AUTOSAR XML (schema 4-3-0)
package /Impl_SWC_FDC_ARPkg
  swc implementation Impl_SWC_FDC_type: programming-language=C, sw-version=1.0.0, vendor-id=0, behavior=SWC_FDC_type_IB
    code-descriptors:
      code SRC: artifact-descriptors=autosar-engineering-object={short-label=EngObject, category=SWSRC}
    resource consumption ResourceConsumption
      memory section MEM_SWC_FDC_CAL: size=0, sw-addrmethod=CAL, symbol=CAL
      memory section MEM_SWC_FDC_CODE: size=0, sw-addrmethod=CODE, symbol=CODE
package /SWC_FDC_ARPkg
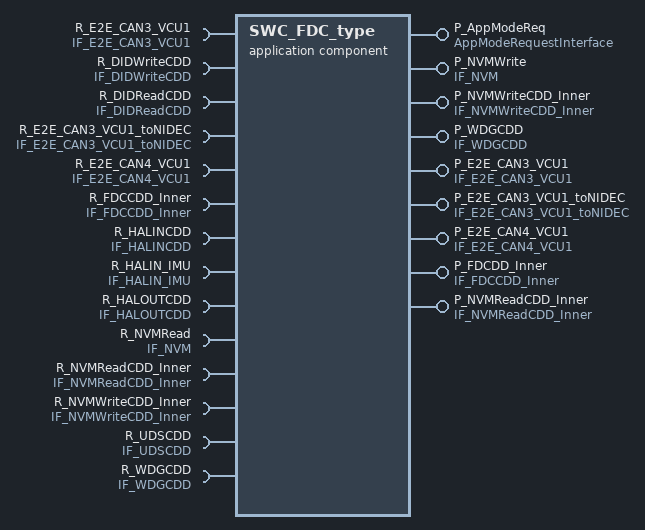
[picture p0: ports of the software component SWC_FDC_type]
  application sw component type SWC_FDC_type
    9 x provide port:
      P_AppModeReq: provided-interface=AppModeRequestInterface
      P_NVMWrite: nv-provide-com-spec{ram-block-init-value=ValueSpecification_:256 x 0, rom-block-init-value=ValueSpecification_:256 x 0, variable=NV_FVTDataArray}, provided-interface=IF_NVM
      P_NVMWriteCDD_Inner: provided-interface=IF_NVMWriteCDD_Inner
      P_WDGCDD: provided-interface=IF_WDGCDD
      P_E2E_CAN3_VCU1: provided-interface=IF_E2E_CAN3_VCU1
      P_E2E_CAN3_VCU1_toNIDEC: provided-interface=IF_E2E_CAN3_VCU1_toNIDEC
      P_E2E_CAN4_VCU1: provided-interface=IF_E2E_CAN4_VCU1
      P_FDCDD_Inner: provided-interface=IF_FDCCDD_Inner
      P_NVMReadCDD_Inner: provided-interface=IF_NVMReadCDD_Inner
    14 x require port:
      R_E2E_CAN3_VCU1: required-interface=IF_E2E_CAN3_VCU1
      R_DIDWriteCDD: required-interface=IF_DIDWriteCDD
      R_DIDReadCDD: required-interface=IF_DIDReadCDD
      R_E2E_CAN3_VCU1_toNIDEC: required-interface=IF_E2E_CAN3_VCU1_toNIDEC
      R_E2E_CAN4_VCU1: required-interface=IF_E2E_CAN4_VCU1
      R_FDCCDD_Inner: required-interface=IF_FDCCDD_Inner
      R_HALINCDD: required-interface=IF_HALINCDD
      R_HALIN_IMU: required-interface=IF_HALIN_IMU
      R_HALOUTCDD: required-interface=IF_HALOUTCDD
      R_NVMRead: nv-require-com-spec{init-value=256 x 0, variable=NV_FVTDataArray}, required-interface=IF_NVM
      R_NVMReadCDD_Inner: required-interface=IF_NVMReadCDD_Inner
      R_NVMWriteCDD_Inner: required-interface=IF_NVMWriteCDD_Inner
      R_UDSCDD: required-interface=IF_UDSCDD
      R_WDGCDD: required-interface=IF_WDGCDD
    behavior SWC_FDC_type_IB: data-type-mapping=AppModeTypeMap, handle-termination-and-restart=NO-SUPPORT
      5 x timing event:
        TE_10ms: start-on-event=run_SWC_FDC_Tx_10ms, period=0.01
        TE_5ms: start-on-event=run_SWC_FDC_RxTx_5ms, period=0.005
        TE_CDD_10ms: start-on-event=run_SWC_FDC_CDD_10ms, period=0.01
        TE_PAS_1ms: start-on-event=run_SWC_FDC_PAS_1ms, period=0.001
        TE_UDS_10ms: start-on-event=run_SWC_FDC_UDS_10ms, period=0.01
      9 x operation invoked event:
        oie_P_E2E_CAN3_VCU1_CSOP_Write_CAN3_VCU1: start-on-event=run_SWC_FDC_E2E_Write_CAN3VCU1, operation=P_E2E_CAN3_VCU1.CSOP_Write_CAN3_VCU1
        oie_P_E2E_CAN3_VCU1_CSOP_Write_CAN3_VCU1_toNIDEC: start-on-event=run_SWC_FDC_E2E_Write_CAN3VCU1_toNIDEC, operation=P_E2E_CAN3_VCU1_toNIDEC.CSOP_Write_CAN3_VCU1_toNIDEC
        oie_P_E2E_CAN4_VCU1_CSOP_Write_CAN4_VCU1: start-on-event=run_SWC_FDC_E2E_Write_CAN4VCU1, operation=P_E2E_CAN4_VCU1.CSOP_Write_CAN4_VCU1
        oie_P_FDCDD_Inner_CSOP_FDC_AppCallSleep: start-on-event=run_SWC_FDC_AppCallSleep, operation=P_FDCDD_Inner.CSOP_FDC_AppCallSleep
        oie_P_NVMReadCDD_Inner_NVM_ReadOperation: start-on-event=run_SWC_FDC_NvmRead, operation=P_NVMReadCDD_Inner.NVM_ReadOperation
        oie_P_NVMWriteCDD_Inner_NVM_WriteOperation: start-on-event=run_SWC_FDC_NvmWrite, operation=P_NVMWriteCDD_Inner.NVM_WriteOperation
        oie_P_WDGCDD_CSOP_Call_WDG_AppEnd: start-on-event=run_SWC_FDC_AppCallWDG_End, operation=P_WDGCDD.CSOP_Call_WDG_AppEnd
        oie_P_WDGCDD_CSOP_Call_WDG_AppStart: start-on-event=run_SWC_FDC_AppCallWDG_StartUp, operation=P_WDGCDD.CSOP_Call_WDG_AppStart
        oie_P_WDGCDD_CSOP_Call_Watchdog: start-on-event=run_SWC_FDC_AppCallWDG, operation=P_WDGCDD.CSOP_Call_Watchdog
      explicit-inter-runnable-variables:
        31 x data:
          IRV_E2E_CAN3_SG_FD3_VCU1: type=DT_CAN3_SG_FD3_VCU1
          IRV_E2E_CAN3_SG_FD3_VCU1_toNIDEC: type=DT_CAN3_SG_FD3_VCU1_toNIDEC
          IRV_E2E_CAN4_SG_FD4_VCU1: type=DT_CAN4_SG_FD4_VCU1
          IRV_f32_ApsOutVehSpdSig: type=float32
          IRV_u8Array12_ApsInDist: type=u8_APSArray12_type
          IRV_u8Array12_ApsInUssSta: type=u8_APSArray12_type
          IRV_u8Array256_NvmReadArray: type=u8_FVTNVMArray256_type
          IRV_u8Array256_NvmWriteArray: type=u8_FVTNVMArray256_type
          IRV_u8Array8_ApsInLevel: type=u8_APSLevelArray8_type
          IRV_u8Array9_TPMSData: type=u8_TPMSDataArray9_type
          IRV_u8_ApsInPASChime: type=uint8
          IRV_u8_ApsInSensorLayout: type=uint8
          IRV_u8_ApsInSysFailSta: type=uint8
          IRV_u8_ApsInSysMode: type=uint8
          IRV_u8_ApsOutGearPosnSig: type=uint8
          IRV_u8_ApsOutSendChrgPlugSta: type=uint8
          IRV_u8_ApsOutSetFrSensorOnCmd: type=uint8
          IRV_u8_ApsOutSetFrSensorSwTOCmd: type=uint8
          IRV_u8_ApsOutSetVehSpdTOCmd: type=uint8
          IRV_u8_CTDSW: type=uint8
          IRV_u8_CrashSignal: type=uint8
          IRV_u8_DrDoorSW: type=uint8
          IRV_u8_HazardSW: type=uint8
          IRV_u8_HoodSW: type=uint8
          IRV_u8_PsDoorSW: type=uint8
          IRV_u8_RLDoorSW: type=uint8
          IRV_u8_RRDoorSW: type=uint8
          IRV_u8_SeatSW: type=uint8
          IRV_u8_TPMSDataInSta: type=boolean
          IRV_u8_TailgateSW: type=uint8
          IRV_u8_TrunkHanSW: type=uint8
      port-api-options:
        enable-take-address=false, indirect-api=false, port=P_FDCDD_Inner
        enable-take-address=false, indirect-api=false, port=P_NVMReadCDD_Inner
        enable-take-address=false, indirect-api=false, port=P_NVMWriteCDD_Inner
        enable-take-address=false, indirect-api=false, port=P_E2E_CAN3_VCU1
        enable-take-address=false, indirect-api=false, port=P_E2E_CAN3_VCU1_toNIDEC
        enable-take-address=false, indirect-api=false, port=P_E2E_CAN4_VCU1
        enable-take-address=false, indirect-api=false, port=P_WDGCDD
      14 x runnable:
        run_SWC_FDC_AppCallSleep
          data-send-points:
            access dsp_requestedMode: accessed-variable=P_AppModeReq.requestedMode
        run_SWC_FDC_AppCallWDG
        run_SWC_FDC_AppCallWDG_End
        run_SWC_FDC_AppCallWDG_StartUp
        run_SWC_FDC_CDD_10ms
          sync call scp_CSOP_HALINCDD_IOEXPANDER: operation=R_HALINCDD.CSOP_HALINCDD_IOEXPANDER, timeout=0.0
          written-local-variables:
            11 x access:
              IRV_u8_CTDSW: accessed-variable=IRV_u8_CTDSW
              IRV_u8_CrashSignal: accessed-variable=IRV_u8_CrashSignal
              IRV_u8_DrDoorSW: accessed-variable=IRV_u8_DrDoorSW
              IRV_u8_HazardSW: accessed-variable=IRV_u8_HazardSW
              IRV_u8_HoodSW: accessed-variable=IRV_u8_HoodSW
              IRV_u8_PsDoorSW: accessed-variable=IRV_u8_PsDoorSW
              IRV_u8_RLDoorSW: accessed-variable=IRV_u8_RLDoorSW
              IRV_u8_RRDoorSW: accessed-variable=IRV_u8_RRDoorSW
              IRV_u8_SeatSW: accessed-variable=IRV_u8_SeatSW
              IRV_u8_TailgateSW: accessed-variable=IRV_u8_TailgateSW
              IRV_u8_TrunkHanSW: accessed-variable=IRV_u8_TrunkHanSW
        run_SWC_FDC_E2E_Write_CAN3VCU1
          data-send-points:
            access dsp_CAN3_SG_FD3_VCU1: accessed-variable=P_CAN3_FD3_VCU1.CAN3_SG_FD3_VCU1
          read-local-variables:
            access IRV_E2E_CAN3_SG_FD3_VCU1: accessed-variable=IRV_E2E_CAN3_SG_FD3_VCU1
        run_SWC_FDC_E2E_Write_CAN3VCU1_toNIDEC
          data-send-points:
            access dsp_CAN3_SG_FD3_VCU1_toNIDEC: accessed-variable=P_CAN3_FD3_VCU1_toNIDEC.CAN3_SG_FD3_VCU1_toNIDEC
          read-local-variables:
            access IRV_E2E_CAN3_SG_FD3_VCU1_toNIDEC: accessed-variable=IRV_E2E_CAN3_SG_FD3_VCU1_toNIDEC
        run_SWC_FDC_E2E_Write_CAN4VCU1
          data-send-points:
            access dsp_CAN4_SG_FD4_VCU1: accessed-variable=P_CAN4_FD4_VCU1.CAN4_SG_FD4_VCU1
          read-local-variables:
            access IRV_E2E_CAN4_SG_FD4_VCU1: accessed-variable=IRV_E2E_CAN4_SG_FD4_VCU1
        run_SWC_FDC_NvmRead
          data-receive-point-by-arguments:
            access drparg_NV_FVTDataArray: accessed-variable=R_NVMRead.NV_FVTDataArray
          written-local-variables:
            access IRV_u8Array256_NvmReadArray: accessed-variable=IRV_u8Array256_NvmReadArray
        run_SWC_FDC_NvmWrite
          data-send-points:
            access dsp_NV_FVTDataArray: accessed-variable=P_NVMWrite.NV_FVTDataArray
          read-local-variables:
            access IRV_u8Array256_NvmWriteArray: accessed-variable=IRV_u8Array256_NvmWriteArray
        run_SWC_FDC_PAS_1ms
          sync call scp_CSOP_PAS_Handler: operation=R_HALINCDD.CSOP_PAS_Handler, timeout=0.0
        run_SWC_FDC_RxTx_5ms
          read-local-variables:
            21 x access:
              IRV_u8Array12_ApsInDist: accessed-variable=IRV_u8Array12_ApsInDist
              IRV_u8Array12_ApsInUssSta: accessed-variable=IRV_u8Array12_ApsInUssSta
              IRV_u8Array256_NvmReadArray: accessed-variable=IRV_u8Array256_NvmReadArray
              IRV_u8Array8_ApsInLevel: accessed-variable=IRV_u8Array8_ApsInLevel
              IRV_u8Array9_TPMSData: accessed-variable=IRV_u8Array9_TPMSData
              IRV_u8_ApsInPASChime: accessed-variable=IRV_u8_ApsInPASChime
              IRV_u8_ApsInSensorLayout: accessed-variable=IRV_u8_ApsInSensorLayout
              IRV_u8_ApsInSysFailSta: accessed-variable=IRV_u8_ApsInSysFailSta
              IRV_u8_ApsInSysMode: accessed-variable=IRV_u8_ApsInSysMode
              IRV_u8_CTDSW: accessed-variable=IRV_u8_CTDSW
              IRV_u8_CrashSignal: accessed-variable=IRV_u8_CrashSignal
              IRV_u8_DrDoorSW: accessed-variable=IRV_u8_DrDoorSW
              IRV_u8_HazardSW: accessed-variable=IRV_u8_HazardSW
              IRV_u8_HoodSW: accessed-variable=IRV_u8_HoodSW
              IRV_u8_PsDoorSW: accessed-variable=IRV_u8_PsDoorSW
              IRV_u8_RLDoorSW: accessed-variable=IRV_u8_RLDoorSW
              IRV_u8_RRDoorSW: accessed-variable=IRV_u8_RRDoorSW
              IRV_u8_SeatSW: accessed-variable=IRV_u8_SeatSW
              IRV_u8_TPMSDataInSta: accessed-variable=IRV_u8_TPMSDataInSta
              IRV_u8_TailgateSW: accessed-variable=IRV_u8_TailgateSW
              IRV_u8_TrunkHanSW: accessed-variable=IRV_u8_TrunkHanSW
          42 x sync call, all with timeout=0.0:
            scp_CSOP_AnyNmID: operation=R_HALINCDD.CSOP_AnyNmID
            scp_CSOP_AppNmStateReq: operation=R_HALOUTCDD.CSOP_AppNmStateReq
            scp_CSOP_GetAcoreRebootCmd: operation=R_HALINCDD.CSOP_GetAcoreRebootCmd
            scp_CSOP_SetAcoreRebootCmdACK: operation=R_HALOUTCDD.CSOP_SetAcoreRebootCmdACK
            scp_CSOP_CAN{1..5}BusOff: operation=R_HALINCDD.CSOP_CAN{1..5}BusOff
            scp_CSOP_Call_WDG_AppEnd: operation=R_WDGCDD.CSOP_Call_WDG_AppEnd
            scp_CSOP_Call_WDG_AppStart: operation=R_WDGCDD.CSOP_Call_WDG_AppStart
            scp_CSOP_Call_Watchdog: operation=R_WDGCDD.CSOP_Call_Watchdog
            scp_CSOP_DIDgetDKCdata: operation=R_HALINCDD.CSOP_DIDgetDKCdata
            scp_CSOP_DIDgetXWDdata: operation=R_HALINCDD.CSOP_DIDgetXWDdata
            scp_CSOP_DKCDecrypt: operation=R_HALINCDD.CSOP_DKCDecrypt
            scp_CSOP_DdmClearDTCNotifica: operation=R_UDSCDD.CSOP_DdmClearDTCNotification
            scp_CSOP_DdmRestartOperation: operation=R_UDSCDD.CSOP_DdmRestartOperationCycle
            scp_CSOP_FDC_AppCallSleep: operation=R_FDCCDD_Inner.CSOP_FDC_AppCallSleep
            scp_CSOP_GetACoreReadyToSleep: operation=R_HALINCDD.CSOP_GetAcoreReadyToSleep
            scp_CSOP_GetAuxBattVoltage: operation=R_HALINCDD.CSOP_GetAuxBattVoltage
            scp_CSOP_GetBootReason: operation=R_HALINCDD.CSOP_GetBootReason
            scp_CSOP_GetEvccAplusPwrUpReq: operation=R_HALINCDD.CSOP_GetEvccAplusPwrUpReq
            scp_CSOP_GetHWID: operation=R_HALINCDD.u8Array4_HWID
            scp_CSOP_GetNmState: operation=R_HALINCDD.CSOP_GetNmState
            scp_CSOP_GetNvmProtectState: operation=R_HALINCDD.CSOP_GetNvmProtectState
            scp_CSOP_GetSWID: operation=R_HALINCDD.CSOP_GetSWID
            scp_CSOP_GetVinpAllowMoveThd: operation=R_HALINCDD.CSOP_GetVinpAllowMoveThdOta
            scp_CSOP_GetVinpPwrReqOta: operation=R_HALINCDD.CSOP_GetVinpPwrReqOta
            scp_CSOP_GetWISR: operation=R_HALINCDD.CSOP_GetWISR
            scp_CSOP_HALINCDD_DIRECT: operation=R_HALINCDD.CSOP_HALINCDD_DIRECT
            scp_CSOP_IVIReset: operation=R_HALOUTCDD.CSOP_IVIReset
            scp_CSOP_IMUGetOffsetVal: operation=R_HALIN_IMU.CSOP_IMUGetOffsetVal
            scp_CSOP_IMUGetSixAxisVal: operation=R_HALIN_IMU.CSOP_IMUGetSixAxisVal
            scp_CSOP_IMUSetSta: operation=R_HALIN_IMU.CSOP_IMUSetSta
            scp_CSOP_SetDTCStatus: operation=R_UDSCDD.CSOP_SetDTCStatus
            scp_CSOP_SetSysPwrStat: operation=R_HALOUTCDD.CSOP_SetSysPwrStat
            scp_CSOP_SleepRequest: operation=R_HALOUTCDD.CSOP_SleepRequest
            scp_CSOP_Write_CAN3_VCU1: operation=R_E2E_CAN3_VCU1.CSOP_Write_CAN3_VCU1
            scp_CSOP_Write_CAN3_VCU1_toNIDEC: operation=R_E2E_CAN3_VCU1_toNIDEC.CSOP_Write_CAN3_VCU1_toNIDEC
            scp_CSOP_Write_CAN4_VCU1: operation=R_E2E_CAN4_VCU1.CSOP_Write_CAN4_VCU1
            scp_NVM_ReadOperation: operation=R_NVMReadCDD_Inner.NVM_ReadOperation
            scp_NVM_WriteOperation: operation=R_NVMWriteCDD_Inner.NVM_WriteOperation
          written-local-variables:
            10 x access:
              IRV_E2E_CAN3_SG_FD3_VCU1: accessed-variable=IRV_E2E_CAN3_SG_FD3_VCU1
              IRV_E2E_CAN3_SG_FD3_VCU1_toNIDEC: accessed-variable=IRV_E2E_CAN3_SG_FD3_VCU1_toNIDEC
              IRV_E2E_CAN4_SG_FD4_VCU1: accessed-variable=IRV_E2E_CAN4_SG_FD4_VCU1
              IRV_f32_ApsOutVehSpdSig: accessed-variable=IRV_f32_ApsOutVehSpdSig
              IRV_u8Array256_NvmWriteArray: accessed-variable=IRV_u8Array256_NvmWriteArray
              IRV_u8_ApsOutGearPosnSig: accessed-variable=IRV_u8_ApsOutGearPosnSig
              IRV_u8_ApsOutSendChrgPlugSta: accessed-variable=IRV_u8_ApsOutSendChrgPlugSta
              IRV_u8_ApsOutSetFrSensorOnCmd: accessed-variable=IRV_u8_ApsOutSetFrSensorOnCmd
              IRV_u8_ApsOutSetFrSensorSwTOCmd: accessed-variable=IRV_u8_ApsOutSetFrSensorSwTOCmd
              IRV_u8_ApsOutSetVehSpdTOCmd: accessed-variable=IRV_u8_ApsOutSetVehSpdTOCmd
        run_SWC_FDC_Tx_10ms
          read-local-variables:
            6 x access:
              IRV_f32_ApsOutVehSpdSig: accessed-variable=IRV_f32_ApsOutVehSpdSig
              IRV_u8_ApsOutGearPosnSig: accessed-variable=IRV_u8_ApsOutGearPosnSig
              IRV_u8_ApsOutSendChrgPlugSta: accessed-variable=IRV_u8_ApsOutSendChrgPlugSta
              IRV_u8_ApsOutSetFrSensorOnCmd: accessed-variable=IRV_u8_ApsOutSetFrSensorOnCmd
              IRV_u8_ApsOutSetFrSensorSwTOCmd: accessed-variable=IRV_u8_ApsOutSetFrSensorSwTOCmd
              IRV_u8_ApsOutSetVehSpdTOCmd: accessed-variable=IRV_u8_ApsOutSetVehSpdTOCmd
          6 x sync call, all with timeout=0.0:
            scp_CSOP_ApsGetDist: operation=R_HALINCDD.CSOP_ApsGetDist
            scp_CSOP_ApsGetDistLevel: operation=R_HALINCDD.CSOP_ApsGetDistLevel
            scp_CSOP_ApsGetUssSta: operation=R_HALINCDD.CSOP_ApsGetUssSta
            scp_CSOP_ApsOutput: operation=R_HALOUTCDD.CSOP_ApsOutput
            scp_CSOP_GetAPSOtherStatus: operation=R_HALINCDD.CSOP_ApsGetOtherStatus
            scp_CSOP_TPMS_GetRawData: operation=R_HALINCDD.CSOP_TPMS_GetRawData
          written-local-variables:
            9 x access:
              IRV_u8Array12_ApsInDist: accessed-variable=IRV_u8Array12_ApsInDist
              IRV_u8Array12_ApsInUssSta: accessed-variable=IRV_u8Array12_ApsInUssSta
              IRV_u8Array8_ApsInLevel: accessed-variable=IRV_u8Array8_ApsInLevel
              IRV_u8Array9_TPMSData: accessed-variable=IRV_u8Array9_TPMSData
              IRV_u8_ApsInPASChime: accessed-variable=IRV_u8_ApsInPASChime
              IRV_u8_ApsInSensorLayout: accessed-variable=IRV_u8_ApsInSensorLayout
              IRV_u8_ApsInSysFailSta: accessed-variable=IRV_u8_ApsInSysFailSta
              IRV_u8_ApsInSysMode: accessed-variable=IRV_u8_ApsInSysMode
              IRV_u8_TPMSDataInSta: accessed-variable=IRV_u8_TPMSDataInSta
        run_SWC_FDC_UDS_10ms
          sync call scp_CSOP_UDS_Main: operation=R_HALINCDD.CSOP_UDS_Main, timeout=0.0
